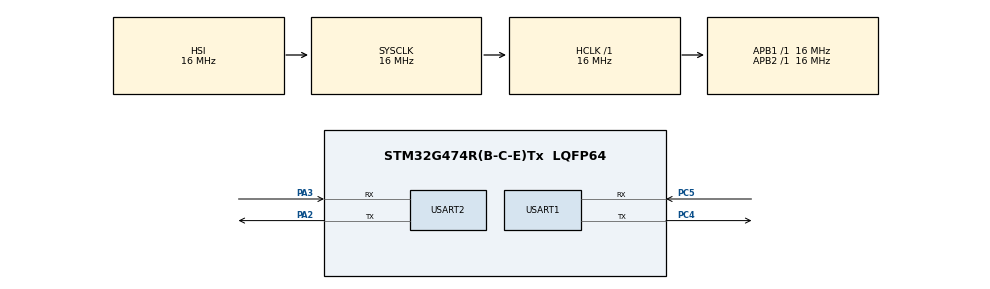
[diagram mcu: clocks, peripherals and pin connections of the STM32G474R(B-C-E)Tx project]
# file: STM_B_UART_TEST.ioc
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Dma.Request0=USART1_RX
Dma.Request1=USART1_TX
Dma.Request2=USART2_RX
Dma.Request3=USART2_TX
Dma.USART1_RX.0.Direction=DMA_PERIPH_TO_MEMORY
Dma.USART1_RX.0.EventEnable=DISABLE
Dma.USART1_RX.0.Instance=DMA1_Channel1
Dma.USART1_RX.0.MemDataAlignment=DMA_MDATAALIGN_BYTE
Dma.USART1_RX.0.MemInc=DMA_MINC_ENABLE
Dma.USART1_RX.0.Mode=DMA_NORMAL
Dma.USART1_RX.0.PeriphDataAlignment=DMA_PDATAALIGN_BYTE
Dma.USART1_RX.0.PeriphInc=DMA_PINC_DISABLE
Dma.USART1_RX.0.Polarity=HAL_DMAMUX_REQ_GEN_RISING
Dma.USART1_RX.0.Priority=DMA_PRIORITY_LOW
Dma.USART1_RX.0.RequestNumber=1
Dma.USART1_RX.0.SignalID=NONE
Dma.USART1_RX.0.SyncEnable=DISABLE
Dma.USART1_RX.0.SyncPolarity=HAL_DMAMUX_SYNC_NO_EVENT
Dma.USART1_RX.0.SyncRequestNumber=1
Dma.USART1_RX.0.SyncSignalID=NONE
Dma.USART1_TX.1.Direction=DMA_MEMORY_TO_PERIPH
Dma.USART1_TX.1.EventEnable=DISABLE
Dma.USART1_TX.1.Instance=DMA1_Channel2
Dma.USART1_TX.1.MemDataAlignment=DMA_MDATAALIGN_BYTE
Dma.USART1_TX.1.MemInc=DMA_MINC_ENABLE
Dma.USART1_TX.1.Mode=DMA_NORMAL
Dma.USART1_TX.1.PeriphDataAlignment=DMA_PDATAALIGN_BYTE
Dma.USART1_TX.1.PeriphInc=DMA_PINC_DISABLE
Dma.USART1_TX.1.Polarity=HAL_DMAMUX_REQ_GEN_RISING
Dma.USART1_TX.1.Priority=DMA_PRIORITY_LOW
Dma.USART1_TX.1.RequestNumber=1
Dma.USART1_TX.1.SignalID=NONE
Dma.USART1_TX.1.SyncEnable=DISABLE
Dma.USART1_TX.1.SyncPolarity=HAL_DMAMUX_SYNC_NO_EVENT
Dma.USART1_TX.1.SyncRequestNumber=1
Dma.USART1_TX.1.SyncSignalID=NONE
Dma.USART2_RX.2.Direction=DMA_PERIPH_TO_MEMORY
Dma.USART2_RX.2.EventEnable=DISABLE
Dma.USART2_RX.2.Instance=DMA1_Channel3
Dma.USART2_RX.2.MemDataAlignment=DMA_MDATAALIGN_BYTE
Dma.USART2_RX.2.MemInc=DMA_MINC_ENABLE
Dma.USART2_RX.2.Mode=DMA_NORMAL
Dma.USART2_RX.2.PeriphDataAlignment=DMA_PDATAALIGN_BYTE
Dma.USART2_RX.2.PeriphInc=DMA_PINC_DISABLE
Dma.USART2_RX.2.Polarity=HAL_DMAMUX_REQ_GEN_RISING
Dma.USART2_RX.2.Priority=DMA_PRIORITY_LOW
Dma.USART2_RX.2.RequestNumber=1
Dma.USART2_RX.2.SignalID=NONE
Dma.USART2_RX.2.SyncEnable=DISABLE
Dma.USART2_RX.2.SyncPolarity=HAL_DMAMUX_SYNC_NO_EVENT
Dma.USART2_RX.2.SyncRequestNumber=1
Dma.USART2_RX.2.SyncSignalID=NONE
Dma.USART2_TX.3.Direction=DMA_MEMORY_TO_PERIPH
Dma.USART2_TX.3.EventEnable=DISABLE
Dma.USART2_TX.3.Instance=DMA1_Channel4
Dma.USART2_TX.3.MemDataAlignment=DMA_MDATAALIGN_BYTE
Dma.USART2_TX.3.MemInc=DMA_MINC_ENABLE
Dma.USART2_TX.3.Mode=DMA_NORMAL
Dma.USART2_TX.3.PeriphDataAlignment=DMA_PDATAALIGN_BYTE
Dma.USART2_TX.3.PeriphInc=DMA_PINC_DISABLE
Dma.USART2_TX.3.Polarity=HAL_DMAMUX_REQ_GEN_RISING
Dma.USART2_TX.3.Priority=DMA_PRIORITY_LOW
Dma.USART2_TX.3.RequestNumber=1
Dma.USART2_TX.3.SignalID=NONE
Dma.USART2_TX.3.SyncEnable=DISABLE
Dma.USART2_TX.3.SyncPolarity=HAL_DMAMUX_SYNC_NO_EVENT
Dma.USART2_TX.3.SyncRequestNumber=1
Dma.USART2_TX.3.SyncSignalID=NONE
FREERTOS.Tasks01=defaultTask,24,128,StartDefaultTask,Default,NULL,Dynamic,NULL,NULL
Mcu.Family=STM32G4
Mcu.Name=STM32G474R(B-C-E)Tx
Mcu.Package=LQFP64
NVIC.DMA1_Channel1_IRQn=true\:5\:0\:false\:false\:true\:true\:false\:true\:true
NVIC.DMA1_Channel2_IRQn=true\:5\:0\:false\:false\:true\:true\:false\:true\:true
NVIC.DMA1_Channel3_IRQn=true\:5\:0\:false\:false\:true\:true\:false\:true\:true
NVIC.DMA1_Channel4_IRQn=true\:5\:0\:false\:false\:true\:true\:false\:true\:true
NVIC.PriorityGroup=NVIC_PRIORITYGROUP_4
NVIC.TIM6_DAC_IRQn=true\:15\:0\:false\:false\:true\:false\:false\:true\:true
NVIC.TimeBase=TIM6_DAC_IRQn
NVIC.TimeBaseIP=TIM6
NVIC.USART1_IRQn=true\:5\:0\:false\:false\:true\:true\:false\:true\:true
NVIC.USART2_IRQn=true\:5\:0\:false\:false\:true\:true\:false\:true\:true
PA2.Mode=Asynchronous
PA2.Signal=USART2_TX
PA3.Mode=Asynchronous
PA3.Signal=USART2_RX
PC4.Mode=Asynchronous
PC4.Signal=USART1_TX
PC5.Mode=Asynchronous
PC5.Signal=USART1_RX
ProjectManager.HeapSize=0x200
ProjectManager.StackSize=0x400
ProjectManager.TargetToolchain=CMake
RCC.AHBFreq_Value=16000000
RCC.APB1Freq_Value=16000000
RCC.APB1TimFreq_Value=16000000
RCC.APB2Freq_Value=16000000
RCC.APB2TimFreq_Value=16000000
RCC.CortexFreq_Value=16000000
RCC.EXTERNAL_CLOCK_VALUE=12288000
RCC.HCLKFreq_Value=16000000
RCC.HSE_VALUE=8000000
RCC.HSI48_VALUE=48000000
RCC.HSI_VALUE=16000000
RCC.LSE_VALUE=32768
RCC.SYSCLKFreq_VALUE=16000000
RCC.USBFreq_Value=64000000
RCC.VCOOutputFreq_Value=128000000
USART1.VirtualMode-Asynchronous=VM_ASYNC
USART2.VirtualMode-Asynchronous=VM_ASYNC
VP_FREERTOS_VS_CMSIS_V2.Mode=CMSIS_V2
VP_SYS_VS_DBSignals.Mode=DisableDeadBatterySignals
VP_SYS_VS_tim6.Mode=TIM6
board=custom

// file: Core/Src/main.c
/* USER CODE BEGIN Header */
/**
  ******************************************************************************
  * @file           : main.c
  * @brief          : Main program body
  ******************************************************************************
  * @attention
  *
  * Copyright (c) 2026 STMicroelectronics.
  * All rights reserved.
  *
  * This software is licensed under terms that can be found in the LICENSE file
  * in the root directory of this software component.
  * If no LICENSE file comes with this software, it is provided AS-IS.
  *
  ******************************************************************************
  */
/* USER CODE END Header */
#include "main.h"
#include "cmsis_os.h"
#include "dma.h"
#include "usart.h"
#include "gpio.h"

void SystemClock_Config(void);
void MX_FREERTOS_Init(void);

int main(void)
{

  /* MCU Configuration--------------------------------------------------------*/

  /* Reset of all peripherals, Initializes the Flash interface and the Systick. */
  HAL_Init();

  /* Configure the system clock */
  SystemClock_Config();

  /* Initialize all configured peripherals */
  MX_GPIO_Init();
  MX_DMA_Init();
  MX_USART1_UART_Init();
  MX_USART2_UART_Init();

  /* Init scheduler */
  osKernelInitialize();  /* Call init function for freertos objects (in cmsis_os2.c) */
  MX_FREERTOS_Init();

  /* Start scheduler */
  osKernelStart();

  /* We should never get here as control is now taken by the scheduler */

  /* Infinite loop */
  while (1)
  {

  }
}

void SystemClock_Config(void)
{
  RCC_OscInitTypeDef RCC_OscInitStruct = {0};
  RCC_ClkInitTypeDef RCC_ClkInitStruct = {0};

  /** Configure the main internal regulator output voltage
  */
  HAL_PWREx_ControlVoltageScaling(PWR_REGULATOR_VOLTAGE_SCALE1);

  /** Initializes the RCC Oscillators according to the specified parameters
  * in the RCC_OscInitTypeDef structure.
  */
  RCC_OscInitStruct.OscillatorType = RCC_OSCILLATORTYPE_HSI;
  RCC_OscInitStruct.HSIState = RCC_HSI_ON;
  RCC_OscInitStruct.HSICalibrationValue = RCC_HSICALIBRATION_DEFAULT;
  RCC_OscInitStruct.PLL.PLLState = RCC_PLL_NONE;
  if (HAL_RCC_OscConfig(&RCC_OscInitStruct) != HAL_OK)
  {
    Error_Handler();
  }

  /** Initializes the CPU, AHB and APB buses clocks
  */
  RCC_ClkInitStruct.ClockType = RCC_CLOCKTYPE_HCLK|RCC_CLOCKTYPE_SYSCLK
                              |RCC_CLOCKTYPE_PCLK1|RCC_CLOCKTYPE_PCLK2;
  RCC_ClkInitStruct.SYSCLKSource = RCC_SYSCLKSOURCE_HSI;
  RCC_ClkInitStruct.AHBCLKDivider = RCC_SYSCLK_DIV1;
  RCC_ClkInitStruct.APB1CLKDivider = RCC_HCLK_DIV1;
  RCC_ClkInitStruct.APB2CLKDivider = RCC_HCLK_DIV1;

  if (HAL_RCC_ClockConfig(&RCC_ClkInitStruct, FLASH_LATENCY_0) != HAL_OK)
  {
    Error_Handler();
  }
}

void HAL_TIM_PeriodElapsedCallback(TIM_HandleTypeDef *htim)
{
  if (htim->Instance == TIM6)
  {
    HAL_IncTick();
  }
}

void Error_Handler(void)
{
  __disable_irq();
  while (1)
  {
  }
}

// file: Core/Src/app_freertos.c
/* USER CODE BEGIN Header */
/**
  ******************************************************************************
  * File Name          : app_freertos.c
  * Description        : Code for freertos applications
  ******************************************************************************
  * @attention
  *
  * Copyright (c) 2026 STMicroelectronics.
  * All rights reserved.
  *
  * This software is licensed under terms that can be found in the LICENSE file
  * in the root directory of this software component.
  * If no LICENSE file comes with this software, it is provided AS-IS.
  *
  ******************************************************************************
  */
/* USER CODE END Header */

#include "FreeRTOS.h"
#include "task.h"
#include "main.h"
#include "cmsis_os.h"

/* USER CODE BEGIN Includes */
#include "usart.h"
/* USER CODE END Includes */

/* Definitions for defaultTask */
osThreadId_t defaultTaskHandle;
const osThreadAttr_t defaultTask_attributes = {
  .name = "defaultTask",
  .priority = (osPriority_t) osPriorityNormal,
  .stack_size = 128 * 4
};

void StartDefaultTask(void *argument);

void MX_FREERTOS_Init(void); /* (MISRA C 2004 rule 8.1) */

void MX_FREERTOS_Init(void) {

  /* Create the thread(s) */
  /* creation of defaultTask */
  defaultTaskHandle = osThreadNew(StartDefaultTask, NULL, &defaultTask_attributes);

}

void StartDefaultTask(void *argument)
{
  /* USER CODE BEGIN StartDefaultTask */
  uint8_t rx_buf[20] = {0};

  // // 보드 A에서 데이터 수신 준비
  // HAL_UART_Receive_DMA(&huart1, rx_buf, 16);

  // for(;;)
  // {
  //   // 받은 데이터를 USART2(VCP)로 PC에 출력
  //   HAL_UART_Transmit(&huart2, rx_buf, 16, 100);
  //   osDelay(600);  // 보드 A 송신 주기(500ms)보다 약간 길게
  // }
  for(;;)
  {
    // 15바이트 수신 대기 (보드 A 송신 크기와 맞춤)
    if(HAL_UART_Receive(&huart1, rx_buf, 15, 2000) == HAL_OK)
    {
      // 받은 데이터 USART2로 PC에 출력
      HAL_UART_Transmit(&huart2, rx_buf, 15, 100);
    }
  }
  /* USER CODE END StartDefaultTask */
}
